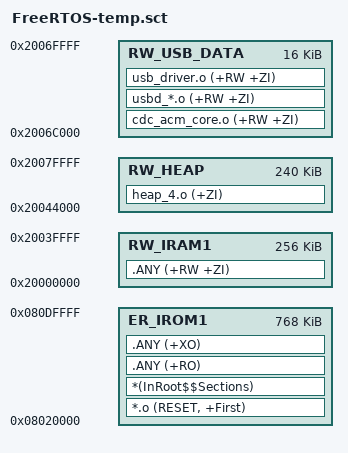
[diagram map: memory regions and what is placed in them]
; *************************************************************
; *** Scatter-Loading Description File generated by uVision ***
; *************************************************************

; App-A 主运行区：0x08020000 ~ 0x080E0000 (768KB)，见 Common/Inc/boot_partition.h
LR_IROM1 0x08020000 0x000C0000  {
  ER_IROM1 0x08020000 0x000C0000  {
   *.o (RESET, +First)
   *(InRoot$$Sections)
   .ANY (+RO)
   .ANY (+XO)
  }

  RW_IRAM1 0x20000000 0x00040000  {
   .ANY (+RW +ZI)
  }

  RW_USB_DATA 0x2006C000 0x00004000 {
    cdc_acm_core.o (+RW +ZI)
    usbd_*.o (+RW +ZI)
    usb_driver.o (+RW +ZI)
  }

  RW_HEAP 0x20044000 0x0003C000  {
    heap_4.o (+ZI)
  }
}
